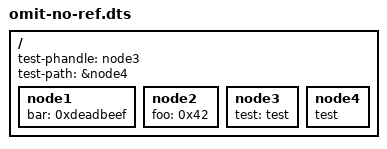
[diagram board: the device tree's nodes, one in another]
/dts-v1/;

/ {
	test-phandle = <&node3>;
	test-path = &node4;

	/omit-if-no-ref/ node1: node1 {
		bar = <0xdeadbeef>;
	};

	node2: node2 {
		foo = <0x42>;
	};

	node3: node3 {
		test = "test";
	};

	node4: node4 {
		test;
	};
};

/omit-if-no-ref/ &node2;
/omit-if-no-ref/ &node3;
/omit-if-no-ref/ &node4;
